VERSION "2"

NS_ :

BS_:

BU_: EyeQ4
VAL_TABLE_ Filter_Type 3 "embedded" 2 "TS on vehicle (truck or bus)" 1 "Irrelevant to the host" ;
VAL_TABLE_ SupplementarySignsTypes 255 "Not in use" 34 "Arrow bidirectional" 33 " Road work au" 32 "area" 31 "Ahead" 30 "Par verglas" 29 "Distance stop" 28 "Reduced ahead" 27 "Minimum" 26 "Advisory" 25 "Exit" 24 "End" 23 "Ramp" 22 "Zone" 21 "Rapel" 20 "Generic supplementary sign" 19 "Night" 18 "Hazardous_Material" 17 "Fog" 16 "Rain_Cloud" 15 "School" 14 "Snow_Rain" 13 "Tractor" 12 "Distance_in" 11 "Weight" 10 "Distance_Arrow" 9 "Truck" 8 "Bend_Arrow_Right" 7 "Bend_Arrow_Left" 6 "ArrowRight" 5 "ArrowLeft" 4 "Time" 3 "Trailer" 2 "Snow" 1 "Rain" ;
VAL_TABLE_ Vision_only_Sign_Type 255 "e_invalid_sign" 254 "No_Sign_Detected" 221 "standardElectronicEndOfNoPassing" 220 "standardElectronicNoPassingStart" 201 "standardRegularEndOfNoPassing" 200 "standardRegularNoPassingStart" 176 "standardRegularEndOfPlaygrArea" 175 "standardRegularPlaygrAreaBegin" 174 "standardRegularEndOfExpressway" 173 "standardRegularExpresswayBegins" 172 "standard regular end of Motorway" 171 "standard regular motorway begins" 129 "standard electronic 145" 128 "standard electronic 135" 127 "standard electronic 125" 126 "standard electronic 115" 125 "standard electronic 105" 124 "standard electronic 95" 123 "standard electronic 85" 122 "standard electronic 75" 121 "standard electronic 65" 120 "standard electronic 55" 119 "standard electronic 45" 118 "standard electronic 35" 117 "standard electronic 25" 116 "standard electronic 15" 115 "standard electronic 5" 114 "standard regular 145" 113 "standard regular 135" 112 "standard regular 125" 111 "standard regular 115" 110 "standard regular 105" 109 "standard regular 95" 108 "standard regular 85" 107 "standard regular 75" 106 "standard regular 65" 105 "standard regular 55" 104 "standard regular 45" 103 "standard regular 35" 102 "standard regular 25" 101 "standard regular 15" 100 "standard regular 5" 65 "standard electronic general" 64 "standard regular general" 50 "end of restriction2" 41 "Standard electronic 140" 40 "Standard electronic 130" 39 "39 Standard electronic 120" 38 "Standard electronic 110" 37 "Standard electronic 100" 36 "Standard electronic 90" 35 "Standard electronic 80" 34 " Standard electronic 70" 33 "Standard electronic 60" 32 "Standard electronic 50" 31 "Standard electronic 40" 30 "Standard electronic 30" 29 "Standard electronic 20" 20 "end of restriction1" 13 "Standard regular 150" 12 "Standard regular 130" 11 "Standard regular 120" 10 "Standard regular 110" 9 "Standard regular 100" 8 "Standard regular 90" 7 "Standard regular 80" 6 "Standard regular 70" 5 "Standard regular 60" 4 "Standard regular 50" 3 "Standard regular 40" 2 "Standard regular 30" 1 "Standard regular 20" 0 "Standard regular 10" ;

BO_ 3221225472 VECTOR__INDEPENDENT_SIG_MSG: 0 Vector__XXX
 SG_ HW_warning_level : 0|2@1+ (1,0) [0|3] "" Vector__XXX
 SG_ TSR_warning_level : 0|3@1+ (1,0) [0|7] "" Vector__XXX
 SG_ R_LDW_availability : 0|1@1+ (1,0) [0|1] "" Vector__XXX
 SG_ PCW : 0|1@1+ (1,0) [0|1] "" Vector__XXX
 SG_ Tamper_Alert : 0|1@1+ (1,0) [0|1] "" Vector__XXX
 SG_ Speed_Format : 0|1@1+ (1,0) [0|1] "" Vector__XXX
 SG_ L_LDW_availability : 0|1@1+ (1,0) [0|1] "" Vector__XXX
 SG_ L_LDW : 0|1@1+ (1,0) [0|1] "" Vector__XXX
 SG_ R_LDW : 0|1@1+ (1,0) [0|1] "" Vector__XXX
 SG_ FCW : 0|1@1+ (1,0) [0|1] "" Vector__XXX
 SG_ Maintenance : 0|1@1+ (1,0) [0|1] "" Vector__XXX
 SG_ Fail_safe : 0|1@1+ (1,0) [0|1] "" Vector__XXX
 SG_ ErrorCode : 0|7@1+ (1,0) [0|127] "" Vector__XXX
 SG_ Headway_valid : 0|1@1+ (1,0) [0|1] "" Vector__XXX
 SG_ Headway_measurements : 0|10@1+ (1,0) [0|1023] "" Vector__XXX
 SG_ TSR_Shape : 0|1@1+ (1,0) [0|1] "" Vector__XXX
 SG_ SLI_Alert : 0|1@1+ (1,0) [0|1] "" Vector__XXX
 SG_ Zero_speed : 0|1@1+ (1,0) [0|1] "" Vector__XXX
 SG_ Hi_Low_beam : 0|1@1+ (1,0) [0|1] "" Vector__XXX
 SG_ FLA_armed : 0|1@1+ (1,0) [0|1] "" Vector__XXX
 SG_ Tiem_indicator : 0|2@1+ (1,0) [0|3] "" Vector__XXX
 SG_ Sound_Type : 0|3@1+ (1,0) [0|7] "" Vector__XXX

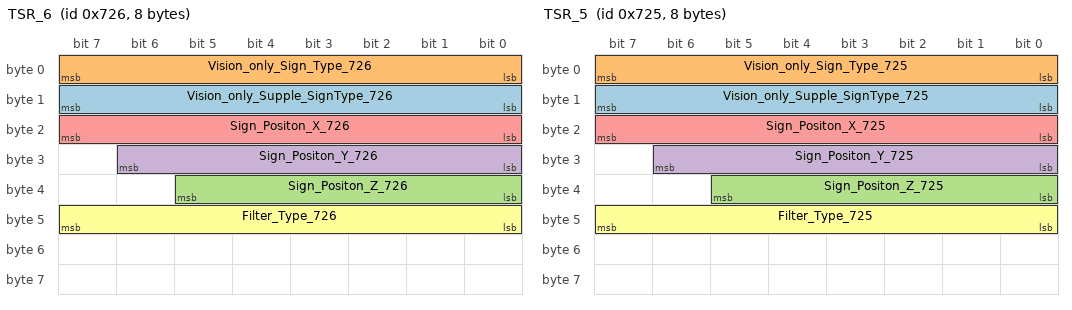
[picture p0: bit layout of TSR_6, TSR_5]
BO_ 1830 TSR_6: 8 EyeQ4
 SG_ Vision_only_Supple_SignType_726 : 8|8@1+ (1,0) [0|255] "" Vector__XXX
 SG_ Vision_only_Sign_Type_726 : 0|8@1+ (1,0) [0|255] "" Vector__XXX
 SG_ Sign_Positon_Z_726 : 32|6@1- (0.5,0) [-16|15.5] "" Vector__XXX
 SG_ Sign_Positon_Y_726 : 24|7@1- (0.5,0) [-32|31.5] "" Vector__XXX
 SG_ Sign_Positon_X_726 : 16|8@1+ (0.5,0) [0|127.5] "" Vector__XXX
 SG_ Filter_Type_726 : 40|8@1+ (1,0) [0|255] "" Vector__XXX

BO_ 1829 TSR_5: 8 EyeQ4
 SG_ Vision_only_Supple_SignType_725 : 8|8@1+ (1,0) [0|255] "" Vector__XXX
 SG_ Vision_only_Sign_Type_725 : 0|8@1+ (1,0) [0|255] "" Vector__XXX
 SG_ Sign_Positon_Z_725 : 32|6@1- (0.5,0) [-16|15.5] "" Vector__XXX
 SG_ Sign_Positon_Y_725 : 24|7@1- (0.5,0) [-32|31.5] "" Vector__XXX
 SG_ Sign_Positon_X_725 : 16|8@1+ (0.5,0) [0|127.5] "" Vector__XXX
 SG_ Filter_Type_725 : 40|8@1+ (1,0) [0|255] "" Vector__XXX

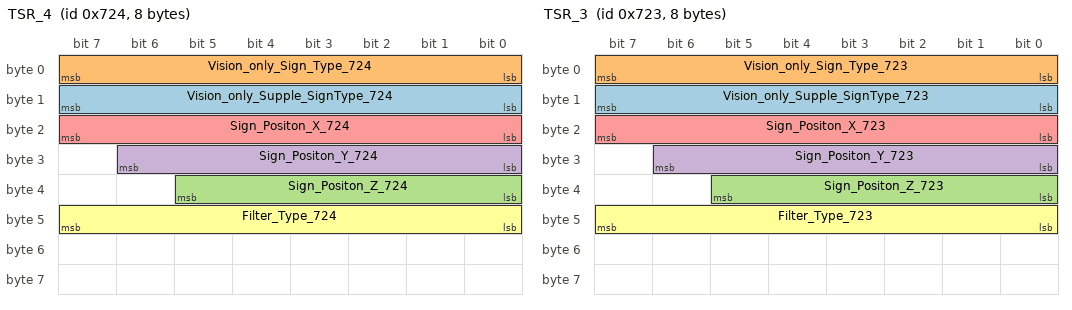
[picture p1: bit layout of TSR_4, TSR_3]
BO_ 1828 TSR_4: 8 EyeQ4
 SG_ Vision_only_Supple_SignType_724 : 8|8@1+ (1,0) [0|255] "" Vector__XXX
 SG_ Vision_only_Sign_Type_724 : 0|8@1+ (1,0) [0|255] "" Vector__XXX
 SG_ Sign_Positon_Z_724 : 32|6@1- (0.5,0) [-16|15.5] "" Vector__XXX
 SG_ Sign_Positon_Y_724 : 24|7@1- (0.5,0) [-32|31.5] "" Vector__XXX
 SG_ Sign_Positon_X_724 : 16|8@1+ (0.5,0) [0|127.5] "" Vector__XXX
 SG_ Filter_Type_724 : 40|8@1+ (1,0) [0|255] "" Vector__XXX

BO_ 1827 TSR_3: 8 EyeQ4
 SG_ Vision_only_Supple_SignType_723 : 8|8@1+ (1,0) [0|255] "" Vector__XXX
 SG_ Vision_only_Sign_Type_723 : 0|8@1+ (1,0) [0|255] "" Vector__XXX
 SG_ Sign_Positon_Z_723 : 32|6@1- (0.5,0) [-16|15.5] "" Vector__XXX
 SG_ Sign_Positon_Y_723 : 24|7@1- (0.5,0) [-32|31.5] "" Vector__XXX
 SG_ Sign_Positon_X_723 : 16|8@1+ (0.5,0) [0|127.5] "" Vector__XXX
 SG_ Filter_Type_723 : 40|8@1+ (1,0) [0|255] "" Vector__XXX

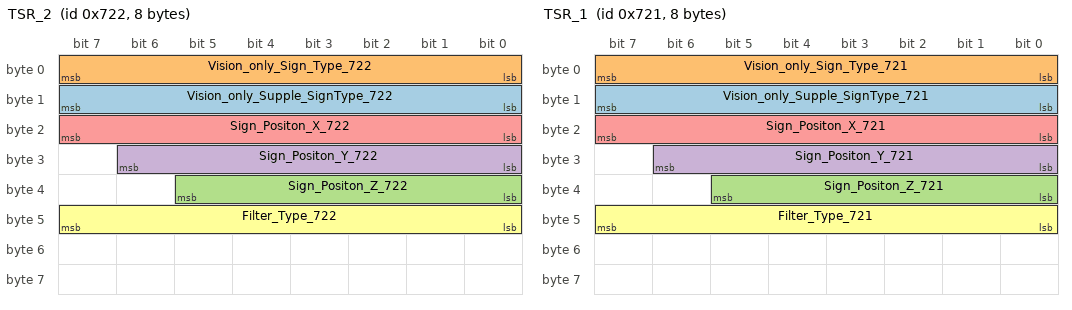
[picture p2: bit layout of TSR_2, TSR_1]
BO_ 1826 TSR_2: 8 EyeQ4
 SG_ Vision_only_Supple_SignType_722 : 8|8@1+ (1,0) [0|255] "" Vector__XXX
 SG_ Vision_only_Sign_Type_722 : 0|8@1+ (1,0) [0|255] "" Vector__XXX
 SG_ Sign_Positon_Z_722 : 32|6@1- (0.5,0) [-16|15.5] "" Vector__XXX
 SG_ Sign_Positon_Y_722 : 24|7@1- (0.5,0) [-32|31.5] "" Vector__XXX
 SG_ Sign_Positon_X_722 : 16|8@1+ (0.5,0) [0|127.5] "" Vector__XXX
 SG_ Filter_Type_722 : 40|8@1+ (1,0) [0|255] "" Vector__XXX

BO_ 1825 TSR_1: 8 EyeQ4
 SG_ Vision_only_Supple_SignType_721 : 8|8@1+ (1,0) [0|255] "" Vector__XXX
 SG_ Vision_only_Sign_Type_721 : 0|8@1+ (1,0) [0|255] "" Vector__XXX
 SG_ Sign_Positon_Z_721 : 32|6@1- (0.5,0) [-16|15.5] "" Vector__XXX
 SG_ Sign_Positon_Y_721 : 24|7@1- (0.5,0) [-32|31.5] "" Vector__XXX
 SG_ Sign_Positon_X_721 : 16|8@1+ (0.5,0) [0|127.5] "" Vector__XXX
 SG_ Filter_Type_721 : 40|8@1+ (1,0) [0|255] "" Vector__XXX

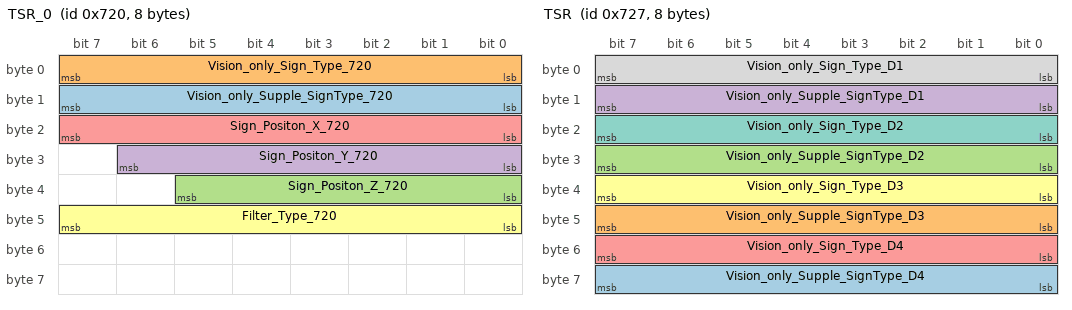
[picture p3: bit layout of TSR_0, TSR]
BO_ 1824 TSR_0: 8 EyeQ4
 SG_ Vision_only_Supple_SignType_720 : 8|8@1+ (1,0) [0|255] "" Vector__XXX
 SG_ Vision_only_Sign_Type_720 : 0|8@1+ (1,0) [0|255] "" Vector__XXX
 SG_ Sign_Positon_Z_720 : 32|6@1- (0.5,0) [-16|15.5] "" Vector__XXX
 SG_ Sign_Positon_Y_720 : 24|7@1- (0.5,0) [-32|31.5] "" Vector__XXX
 SG_ Sign_Positon_X_720 : 16|8@1+ (0.5,0) [0|127.5] "" Vector__XXX
 SG_ Filter_Type_720 : 40|8@1+ (1,0) [0|255] "" Vector__XXX

BO_ 1831 TSR: 8 EyeQ4
 SG_ Vision_only_Supple_SignType_D4 : 56|8@1+ (1,0) [0|255] "" Vector__XXX
 SG_ Vision_only_Supple_SignType_D3 : 40|8@1+ (1,0) [0|255] "" Vector__XXX
 SG_ Vision_only_Supple_SignType_D2 : 24|8@1+ (1,0) [0|255] "" Vector__XXX
 SG_ Vision_only_Supple_SignType_D1 : 8|8@1+ (1,0) [0|255] "" Vector__XXX
 SG_ Vision_only_Sign_Type_D4 : 48|8@1+ (1,0) [0|255] "" Vector__XXX
 SG_ Vision_only_Sign_Type_D3 : 32|8@1+ (1,0) [0|255] "" Vector__XXX
 SG_ Vision_only_Sign_Type_D2 : 16|8@1+ (1,0) [0|255] "" Vector__XXX
 SG_ Vision_only_Sign_Type_D1 : 0|8@1+ (1,0) [0|255] "" Vector__XXX

CM_ BO_ 3221225472 "This is a message for not used signals, created by Vector CANdb++ DBC OLE DB Provider.";
BA_DEF_  "BusType" STRING ;
BA_DEF_DEF_  "BusType" "CAN";
VAL_ 1830 Vision_only_Supple_SignType_726 255 "Not in use" 34 "Arrow bidirectional" 33 " Road work au" 32 "area" 31 "Ahead" 30 "Par verglas" 29 "Distance stop" 28 "Reduced ahead" 27 "Minimum" 26 "Advisory" 25 "Exit" 24 "End" 23 "Ramp" 22 "Zone" 21 "Rapel" 20 "Generic supplementary sign" 19 "Night" 18 "Hazardous_Material" 17 "Fog" 16 "Rain_Cloud" 15 "School" 14 "Snow_Rain" 13 "Tractor" 12 "Distance_in" 11 "Weight" 10 "Distance_Arrow" 9 "Truck" 8 "Bend_Arrow_Right" 7 "Bend_Arrow_Left" 6 "ArrowRight" 5 "ArrowLeft" 4 "Time" 3 "Trailer" 2 "Snow" 1 "Rain" ;
VAL_ 1830 Vision_only_Sign_Type_726 255 "e_invalid_sign" 254 "No_Sign_Detected" 221 "standardElectronicEndOfNoPassing" 220 "standardElectronicNoPassingStart" 201 "standardRegularEndOfNoPassing" 200 "standardRegularNoPassingStart" 176 "standardRegularEndOfPlaygrArea" 175 "standardRegularPlaygrAreaBegin" 174 "standardRegularEndOfExpressway" 173 "standardRegularExpresswayBegins" 172 "standard regular end of Motorway" 171 "standard regular motorway begins" 129 "standard electronic 145" 128 "standard electronic 135" 127 "standard electronic 125" 126 "standard electronic 115" 125 "standard electronic 105" 124 "standard electronic 95" 123 "standard electronic 85" 122 "standard electronic 75" 121 "standard electronic 65" 120 "standard electronic 55" 119 "standard electronic 45" 118 "standard electronic 35" 117 "standard electronic 25" 116 "standard electronic 15" 115 "standard electronic 5" 114 "standard regular 145" 113 "standard regular 135" 112 "standard regular 125" 111 "standard regular 115" 110 "standard regular 105" 109 "standard regular 95" 108 "standard regular 85" 107 "standard regular 75" 106 "standard regular 65" 105 "standard regular 55" 104 "standard regular 45" 103 "standard regular 35" 102 "standard regular 25" 101 "standard regular 15" 100 "standard regular 5" 65 "standard electronic general" 64 "standard regular general" 50 "end of restriction2" 41 "Standard electronic 140" 40 "Standard electronic 130" 39 "39 Standard electronic 120" 38 "Standard electronic 110" 37 "Standard electronic 100" 36 "Standard electronic 90" 35 "Standard electronic 80" 34 " Standard electronic 70" 33 "Standard electronic 60" 32 "Standard electronic 50" 31 "Standard electronic 40" 30 "Standard electronic 30" 29 "Standard electronic 20" 20 "end of restriction1" 13 "Standard regular 150" 12 "Standard regular 130" 11 "Standard regular 120" 10 "Standard regular 110" 9 "Standard regular 100" 8 "Standard regular 90" 7 "Standard regular 80" 6 "Standard regular 70" 5 "Standard regular 60" 4 "Standard regular 50" 3 "Standard regular 40" 2 "Standard regular 30" 1 "Standard regular 20" 0 "Standard regular 10" ;
VAL_ 1830 Filter_Type_726 3 "embedded" 2 "TS on vehicle (truck or bus)" 1 "Irrelevant to the host" ;
VAL_ 1829 Vision_only_Supple_SignType_725 255 "Not in use" 34 "Arrow bidirectional" 33 " Road work au" 32 "area" 31 "Ahead" 30 "Par verglas" 29 "Distance stop" 28 "Reduced ahead" 27 "Minimum" 26 "Advisory" 25 "Exit" 24 "End" 23 "Ramp" 22 "Zone" 21 "Rapel" 20 "Generic supplementary sign" 19 "Night" 18 "Hazardous_Material" 17 "Fog" 16 "Rain_Cloud" 15 "School" 14 "Snow_Rain" 13 "Tractor" 12 "Distance_in" 11 "Weight" 10 "Distance_Arrow" 9 "Truck" 8 "Bend_Arrow_Right" 7 "Bend_Arrow_Left" 6 "ArrowRight" 5 "ArrowLeft" 4 "Time" 3 "Trailer" 2 "Snow" 1 "Rain" ;
VAL_ 1829 Vision_only_Sign_Type_725 255 "e_invalid_sign" 254 "No_Sign_Detected" 221 "standardElectronicEndOfNoPassing" 220 "standardElectronicNoPassingStart" 201 "standardRegularEndOfNoPassing" 200 "standardRegularNoPassingStart" 176 "standardRegularEndOfPlaygrArea" 175 "standardRegularPlaygrAreaBegin" 174 "standardRegularEndOfExpressway" 173 "standardRegularExpresswayBegins" 172 "standard regular end of Motorway" 171 "standard regular motorway begins" 129 "standard electronic 145" 128 "standard electronic 135" 127 "standard electronic 125" 126 "standard electronic 115" 125 "standard electronic 105" 124 "standard electronic 95" 123 "standard electronic 85" 122 "standard electronic 75" 121 "standard electronic 65" 120 "standard electronic 55" 119 "standard electronic 45" 118 "standard electronic 35" 117 "standard electronic 25" 116 "standard electronic 15" 115 "standard electronic 5" 114 "standard regular 145" 113 "standard regular 135" 112 "standard regular 125" 111 "standard regular 115" 110 "standard regular 105" 109 "standard regular 95" 108 "standard regular 85" 107 "standard regular 75" 106 "standard regular 65" 105 "standard regular 55" 104 "standard regular 45" 103 "standard regular 35" 102 "standard regular 25" 101 "standard regular 15" 100 "standard regular 5" 65 "standard electronic general" 64 "standard regular general" 50 "end of restriction2" 41 "Standard electronic 140" 40 "Standard electronic 130" 39 "39 Standard electronic 120" 38 "Standard electronic 110" 37 "Standard electronic 100" 36 "Standard electronic 90" 35 "Standard electronic 80" 34 " Standard electronic 70" 33 "Standard electronic 60" 32 "Standard electronic 50" 31 "Standard electronic 40" 30 "Standard electronic 30" 29 "Standard electronic 20" 20 "end of restriction1" 13 "Standard regular 150" 12 "Standard regular 130" 11 "Standard regular 120" 10 "Standard regular 110" 9 "Standard regular 100" 8 "Standard regular 90" 7 "Standard regular 80" 6 "Standard regular 70" 5 "Standard regular 60" 4 "Standard regular 50" 3 "Standard regular 40" 2 "Standard regular 30" 1 "Standard regular 20" 0 "Standard regular 10" ;
VAL_ 1829 Filter_Type_725 3 "embedded" 2 "TS on vehicle (truck or bus)" 1 "Irrelevant to the host" ;
VAL_ 1828 Vision_only_Supple_SignType_724 255 "Not in use" 34 "Arrow bidirectional" 33 " Road work au" 32 "area" 31 "Ahead" 30 "Par verglas" 29 "Distance stop" 28 "Reduced ahead" 27 "Minimum" 26 "Advisory" 25 "Exit" 24 "End" 23 "Ramp" 22 "Zone" 21 "Rapel" 20 "Generic supplementary sign" 19 "Night" 18 "Hazardous_Material" 17 "Fog" 16 "Rain_Cloud" 15 "School" 14 "Snow_Rain" 13 "Tractor" 12 "Distance_in" 11 "Weight" 10 "Distance_Arrow" 9 "Truck" 8 "Bend_Arrow_Right" 7 "Bend_Arrow_Left" 6 "ArrowRight" 5 "ArrowLeft" 4 "Time" 3 "Trailer" 2 "Snow" 1 "Rain" ;
VAL_ 1828 Vision_only_Sign_Type_724 255 "e_invalid_sign" 254 "No_Sign_Detected" 221 "standardElectronicEndOfNoPassing" 220 "standardElectronicNoPassingStart" 201 "standardRegularEndOfNoPassing" 200 "standardRegularNoPassingStart" 176 "standardRegularEndOfPlaygrArea" 175 "standardRegularPlaygrAreaBegin" 174 "standardRegularEndOfExpressway" 173 "standardRegularExpresswayBegins" 172 "standard regular end of Motorway" 171 "standard regular motorway begins" 129 "standard electronic 145" 128 "standard electronic 135" 127 "standard electronic 125" 126 "standard electronic 115" 125 "standard electronic 105" 124 "standard electronic 95" 123 "standard electronic 85" 122 "standard electronic 75" 121 "standard electronic 65" 120 "standard electronic 55" 119 "standard electronic 45" 118 "standard electronic 35" 117 "standard electronic 25" 116 "standard electronic 15" 115 "standard electronic 5" 114 "standard regular 145" 113 "standard regular 135" 112 "standard regular 125" 111 "standard regular 115" 110 "standard regular 105" 109 "standard regular 95" 108 "standard regular 85" 107 "standard regular 75" 106 "standard regular 65" 105 "standard regular 55" 104 "standard regular 45" 103 "standard regular 35" 102 "standard regular 25" 101 "standard regular 15" 100 "standard regular 5" 65 "standard electronic general" 64 "standard regular general" 50 "end of restriction2" 41 "Standard electronic 140" 40 "Standard electronic 130" 39 "39 Standard electronic 120" 38 "Standard electronic 110" 37 "Standard electronic 100" 36 "Standard electronic 90" 35 "Standard electronic 80" 34 " Standard electronic 70" 33 "Standard electronic 60" 32 "Standard electronic 50" 31 "Standard electronic 40" 30 "Standard electronic 30" 29 "Standard electronic 20" 20 "end of restriction1" 13 "Standard regular 150" 12 "Standard regular 130" 11 "Standard regular 120" 10 "Standard regular 110" 9 "Standard regular 100" 8 "Standard regular 90" 7 "Standard regular 80" 6 "Standard regular 70" 5 "Standard regular 60" 4 "Standard regular 50" 3 "Standard regular 40" 2 "Standard regular 30" 1 "Standard regular 20" 0 "Standard regular 10" ;
VAL_ 1828 Filter_Type_724 3 "embedded" 2 "TS on vehicle (truck or bus)" 1 "Irrelevant to the host" ;
VAL_ 1827 Vision_only_Supple_SignType_723 255 "Not in use" 34 "Arrow bidirectional" 33 " Road work au" 32 "area" 31 "Ahead" 30 "Par verglas" 29 "Distance stop" 28 "Reduced ahead" 27 "Minimum" 26 "Advisory" 25 "Exit" 24 "End" 23 "Ramp" 22 "Zone" 21 "Rapel" 20 "Generic supplementary sign" 19 "Night" 18 "Hazardous_Material" 17 "Fog" 16 "Rain_Cloud" 15 "School" 14 "Snow_Rain" 13 "Tractor" 12 "Distance_in" 11 "Weight" 10 "Distance_Arrow" 9 "Truck" 8 "Bend_Arrow_Right" 7 "Bend_Arrow_Left" 6 "ArrowRight" 5 "ArrowLeft" 4 "Time" 3 "Trailer" 2 "Snow" 1 "Rain" ;
VAL_ 1827 Vision_only_Sign_Type_723 255 "e_invalid_sign" 254 "No_Sign_Detected" 221 "standardElectronicEndOfNoPassing" 220 "standardElectronicNoPassingStart" 201 "standardRegularEndOfNoPassing" 200 "standardRegularNoPassingStart" 176 "standardRegularEndOfPlaygrArea" 175 "standardRegularPlaygrAreaBegin" 174 "standardRegularEndOfExpressway" 173 "standardRegularExpresswayBegins" 172 "standard regular end of Motorway" 171 "standard regular motorway begins" 129 "standard electronic 145" 128 "standard electronic 135" 127 "standard electronic 125" 126 "standard electronic 115" 125 "standard electronic 105" 124 "standard electronic 95" 123 "standard electronic 85" 122 "standard electronic 75" 121 "standard electronic 65" 120 "standard electronic 55" 119 "standard electronic 45" 118 "standard electronic 35" 117 "standard electronic 25" 116 "standard electronic 15" 115 "standard electronic 5" 114 "standard regular 145" 113 "standard regular 135" 112 "standard regular 125" 111 "standard regular 115" 110 "standard regular 105" 109 "standard regular 95" 108 "standard regular 85" 107 "standard regular 75" 106 "standard regular 65" 105 "standard regular 55" 104 "standard regular 45" 103 "standard regular 35" 102 "standard regular 25" 101 "standard regular 15" 100 "standard regular 5" 65 "standard electronic general" 64 "standard regular general" 50 "end of restriction2" 41 "Standard electronic 140" 40 "Standard electronic 130" 39 "39 Standard electronic 120" 38 "Standard electronic 110" 37 "Standard electronic 100" 36 "Standard electronic 90" 35 "Standard electronic 80" 34 " Standard electronic 70" 33 "Standard electronic 60" 32 "Standard electronic 50" 31 "Standard electronic 40" 30 "Standard electronic 30" 29 "Standard electronic 20" 20 "end of restriction1" 13 "Standard regular 150" 12 "Standard regular 130" 11 "Standard regular 120" 10 "Standard regular 110" 9 "Standard regular 100" 8 "Standard regular 90" 7 "Standard regular 80" 6 "Standard regular 70" 5 "Standard regular 60" 4 "Standard regular 50" 3 "Standard regular 40" 2 "Standard regular 30" 1 "Standard regular 20" 0 "Standard regular 10" ;
VAL_ 1827 Filter_Type_723 3 "embedded" 2 "TS on vehicle (truck or bus)" 1 "Irrelevant to the host" ;
VAL_ 1826 Vision_only_Supple_SignType_722 255 "Not in use" 34 "Arrow bidirectional" 33 " Road work au" 32 "area" 31 "Ahead" 30 "Par verglas" 29 "Distance stop" 28 "Reduced ahead" 27 "Minimum" 26 "Advisory" 25 "Exit" 24 "End" 23 "Ramp" 22 "Zone" 21 "Rapel" 20 "Generic supplementary sign" 19 "Night" 18 "Hazardous_Material" 17 "Fog" 16 "Rain_Cloud" 15 "School" 14 "Snow_Rain" 13 "Tractor" 12 "Distance_in" 11 "Weight" 10 "Distance_Arrow" 9 "Truck" 8 "Bend_Arrow_Right" 7 "Bend_Arrow_Left" 6 "ArrowRight" 5 "ArrowLeft" 4 "Time" 3 "Trailer" 2 "Snow" 1 "Rain" ;
VAL_ 1826 Vision_only_Sign_Type_722 255 "e_invalid_sign" 254 "No_Sign_Detected" 221 "standardElectronicEndOfNoPassing" 220 "standardElectronicNoPassingStart" 201 "standardRegularEndOfNoPassing" 200 "standardRegularNoPassingStart" 176 "standardRegularEndOfPlaygrArea" 175 "standardRegularPlaygrAreaBegin" 174 "standardRegularEndOfExpressway" 173 "standardRegularExpresswayBegins" 172 "standard regular end of Motorway" 171 "standard regular motorway begins" 129 "standard electronic 145" 128 "standard electronic 135" 127 "standard electronic 125" 126 "standard electronic 115" 125 "standard electronic 105" 124 "standard electronic 95" 123 "standard electronic 85" 122 "standard electronic 75" 121 "standard electronic 65" 120 "standard electronic 55" 119 "standard electronic 45" 118 "standard electronic 35" 117 "standard electronic 25" 116 "standard electronic 15" 115 "standard electronic 5" 114 "standard regular 145" 113 "standard regular 135" 112 "standard regular 125" 111 "standard regular 115" 110 "standard regular 105" 109 "standard regular 95" 108 "standard regular 85" 107 "standard regular 75" 106 "standard regular 65" 105 "standard regular 55" 104 "standard regular 45" 103 "standard regular 35" 102 "standard regular 25" 101 "standard regular 15" 100 "standard regular 5" 65 "standard electronic general" 64 "standard regular general" 50 "end of restriction2" 41 "Standard electronic 140" 40 "Standard electronic 130" 39 "39 Standard electronic 120" 38 "Standard electronic 110" 37 "Standard electronic 100" 36 "Standard electronic 90" 35 "Standard electronic 80" 34 " Standard electronic 70" 33 "Standard electronic 60" 32 "Standard electronic 50" 31 "Standard electronic 40" 30 "Standard electronic 30" 29 "Standard electronic 20" 20 "end of restriction1" 13 "Standard regular 150" 12 "Standard regular 130" 11 "Standard regular 120" 10 "Standard regular 110" 9 "Standard regular 100" 8 "Standard regular 90" 7 "Standard regular 80" 6 "Standard regular 70" 5 "Standard regular 60" 4 "Standard regular 50" 3 "Standard regular 40" 2 "Standard regular 30" 1 "Standard regular 20" 0 "Standard regular 10" ;
VAL_ 1826 Filter_Type_722 3 "embedded" 2 "TS on vehicle (truck or bus)" 1 "Irrelevant to the host" ;
VAL_ 1825 Vision_only_Supple_SignType_721 255 "Not in use" 34 "Arrow bidirectional" 33 " Road work au" 32 "area" 31 "Ahead" 30 "Par verglas" 29 "Distance stop" 28 "Reduced ahead" 27 "Minimum" 26 "Advisory" 25 "Exit" 24 "End" 23 "Ramp" 22 "Zone" 21 "Rapel" 20 "Generic supplementary sign" 19 "Night" 18 "Hazardous_Material" 17 "Fog" 16 "Rain_Cloud" 15 "School" 14 "Snow_Rain" 13 "Tractor" 12 "Distance_in" 11 "Weight" 10 "Distance_Arrow" 9 "Truck" 8 "Bend_Arrow_Right" 7 "Bend_Arrow_Left" 6 "ArrowRight" 5 "ArrowLeft" 4 "Time" 3 "Trailer" 2 "Snow" 1 "Rain" ;
VAL_ 1825 Vision_only_Sign_Type_721 255 "e_invalid_sign" 254 "No_Sign_Detected" 221 "standardElectronicEndOfNoPassing" 220 "standardElectronicNoPassingStart" 201 "standardRegularEndOfNoPassing" 200 "standardRegularNoPassingStart" 176 "standardRegularEndOfPlaygrArea" 175 "standardRegularPlaygrAreaBegin" 174 "standardRegularEndOfExpressway" 173 "standardRegularExpresswayBegins" 172 "standard regular end of Motorway" 171 "standard regular motorway begins" 129 "standard electronic 145" 128 "standard electronic 135" 127 "standard electronic 125" 126 "standard electronic 115" 125 "standard electronic 105" 124 "standard electronic 95" 123 "standard electronic 85" 122 "standard electronic 75" 121 "standard electronic 65" 120 "standard electronic 55" 119 "standard electronic 45" 118 "standard electronic 35" 117 "standard electronic 25" 116 "standard electronic 15" 115 "standard electronic 5" 114 "standard regular 145" 113 "standard regular 135" 112 "standard regular 125" 111 "standard regular 115" 110 "standard regular 105" 109 "standard regular 95" 108 "standard regular 85" 107 "standard regular 75" 106 "standard regular 65" 105 "standard regular 55" 104 "standard regular 45" 103 "standard regular 35" 102 "standard regular 25" 101 "standard regular 15" 100 "standard regular 5" 65 "standard electronic general" 64 "standard regular general" 50 "end of restriction2" 41 "Standard electronic 140" 40 "Standard electronic 130" 39 "39 Standard electronic 120" 38 "Standard electronic 110" 37 "Standard electronic 100" 36 "Standard electronic 90" 35 "Standard electronic 80" 34 " Standard electronic 70" 33 "Standard electronic 60" 32 "Standard electronic 50" 31 "Standard electronic 40" 30 "Standard electronic 30" 29 "Standard electronic 20" 20 "end of restriction1" 13 "Standard regular 150" 12 "Standard regular 130" 11 "Standard regular 120" 10 "Standard regular 110" 9 "Standard regular 100" 8 "Standard regular 90" 7 "Standard regular 80" 6 "Standard regular 70" 5 "Standard regular 60" 4 "Standard regular 50" 3 "Standard regular 40" 2 "Standard regular 30" 1 "Standard regular 20" 0 "Standard regular 10" ;
VAL_ 1825 Filter_Type_721 3 "embedded" 2 "TS on vehicle (truck or bus)" 1 "Irrelevant to the host" ;
VAL_ 1824 Vision_only_Supple_SignType_720 255 "Not in use" 34 "Arrow bidirectional" 33 " Road work au" 32 "area" 31 "Ahead" 30 "Par verglas" 29 "Distance stop" 28 "Reduced ahead" 27 "Minimum" 26 "Advisory" 25 "Exit" 24 "End" 23 "Ramp" 22 "Zone" 21 "Rapel" 20 "Generic supplementary sign" 19 "Night" 18 "Hazardous_Material" 17 "Fog" 16 "Rain_Cloud" 15 "School" 14 "Snow_Rain" 13 "Tractor" 12 "Distance_in" 11 "Weight" 10 "Distance_Arrow" 9 "Truck" 8 "Bend_Arrow_Right" 7 "Bend_Arrow_Left" 6 "ArrowRight" 5 "ArrowLeft" 4 "Time" 3 "Trailer" 2 "Snow" 1 "Rain" ;
VAL_ 1824 Vision_only_Sign_Type_720 255 "e_invalid_sign" 254 "No_Sign_Detected" 221 "standardElectronicEndOfNoPassing" 220 "standardElectronicNoPassingStart" 201 "standardRegularEndOfNoPassing" 200 "standardRegularNoPassingStart" 176 "standardRegularEndOfPlaygrArea" 175 "standardRegularPlaygrAreaBegin" 174 "standardRegularEndOfExpressway" 173 "standardRegularExpresswayBegins" 172 "standard regular end of Motorway" 171 "standard regular motorway begins" 129 "standard electronic 145" 128 "standard electronic 135" 127 "standard electronic 125" 126 "standard electronic 115" 125 "standard electronic 105" 124 "standard electronic 95" 123 "standard electronic 85" 122 "standard electronic 75" 121 "standard electronic 65" 120 "standard electronic 55" 119 "standard electronic 45" 118 "standard electronic 35" 117 "standard electronic 25" 116 "standard electronic 15" 115 "standard electronic 5" 114 "standard regular 145" 113 "standard regular 135" 112 "standard regular 125" 111 "standard regular 115" 110 "standard regular 105" 109 "standard regular 95" 108 "standard regular 85" 107 "standard regular 75" 106 "standard regular 65" 105 "standard regular 55" 104 "standard regular 45" 103 "standard regular 35" 102 "standard regular 25" 101 "standard regular 15" 100 "standard regular 5" 65 "standard electronic general" 64 "standard regular general" 50 "end of restriction2" 41 "Standard electronic 140" 40 "Standard electronic 130" 39 "39 Standard electronic 120" 38 "Standard electronic 110" 37 "Standard electronic 100" 36 "Standard electronic 90" 35 "Standard electronic 80" 34 " Standard electronic 70" 33 "Standard electronic 60" 32 "Standard electronic 50" 31 "Standard electronic 40" 30 "Standard electronic 30" 29 "Standard electronic 20" 20 "end of restriction1" 13 "Standard regular 150" 12 "Standard regular 130" 11 "Standard regular 120" 10 "Standard regular 110" 9 "Standard regular 100" 8 "Standard regular 90" 7 "Standard regular 80" 6 "Standard regular 70" 5 "Standard regular 60" 4 "Standard regular 50" 3 "Standard regular 40" 2 "Standard regular 30" 1 "Standard regular 20" 0 "Standard regular 10" ;
VAL_ 1824 Filter_Type_720 3 "embedded" 2 "TS on vehicle (truck or bus)" 1 "Irrelevant to the host" ;
VAL_ 1831 Vision_only_Supple_SignType_D4 255 "Not in use" 34 "Arrow bidirectional" 33 " Road work au" 32 "area" 31 "Ahead" 30 "Par verglas" 29 "Distance stop" 28 "Reduced ahead" 27 "Minimum" 26 "Advisory" 25 "Exit" 24 "End" 23 "Ramp" 22 "Zone" 21 "Rapel" 20 "Generic supplementary sign" 19 "Night" 18 "Hazardous_Material" 17 "Fog" 16 "Rain_Cloud" 15 "School" 14 "Snow_Rain" 13 "Tractor" 12 "Distance_in" 11 "Weight" 10 "Distance_Arrow" 9 "Truck" 8 "Bend_Arrow_Right" 7 "Bend_Arrow_Left" 6 "ArrowRight" 5 "ArrowLeft" 4 "Time" 3 "Trailer" 2 "Snow" 1 "Rain" ;
VAL_ 1831 Vision_only_Supple_SignType_D3 255 "Not in use" 34 "Arrow bidirectional" 33 " Road work au" 32 "area" 31 "Ahead" 30 "Par verglas" 29 "Distance stop" 28 "Reduced ahead" 27 "Minimum" 26 "Advisory" 25 "Exit" 24 "End" 23 "Ramp" 22 "Zone" 21 "Rapel" 20 "Generic supplementary sign" 19 "Night" 18 "Hazardous_Material" 17 "Fog" 16 "Rain_Cloud" 15 "School" 14 "Snow_Rain" 13 "Tractor" 12 "Distance_in" 11 "Weight" 10 "Distance_Arrow" 9 "Truck" 8 "Bend_Arrow_Right" 7 "Bend_Arrow_Left" 6 "ArrowRight" 5 "ArrowLeft" 4 "Time" 3 "Trailer" 2 "Snow" 1 "Rain" ;
VAL_ 1831 Vision_only_Supple_SignType_D2 255 "Not in use" 34 "Arrow bidirectional" 33 " Road work au" 32 "area" 31 "Ahead" 30 "Par verglas" 29 "Distance stop" 28 "Reduced ahead" 27 "Minimum" 26 "Advisory" 25 "Exit" 24 "End" 23 "Ramp" 22 "Zone" 21 "Rapel" 20 "Generic supplementary sign" 19 "Night" 18 "Hazardous_Material" 17 "Fog" 16 "Rain_Cloud" 15 "School" 14 "Snow_Rain" 13 "Tractor" 12 "Distance_in" 11 "Weight" 10 "Distance_Arrow" 9 "Truck" 8 "Bend_Arrow_Right" 7 "Bend_Arrow_Left" 6 "ArrowRight" 5 "ArrowLeft" 4 "Time" 3 "Trailer" 2 "Snow" 1 "Rain" ;
VAL_ 1831 Vision_only_Supple_SignType_D1 255 "Not in use" 34 "Arrow bidirectional" 33 " Road work au" 32 "area" 31 "Ahead" 30 "Par verglas" 29 "Distance stop" 28 "Reduced ahead" 27 "Minimum" 26 "Advisory" 25 "Exit" 24 "End" 23 "Ramp" 22 "Zone" 21 "Rapel" 20 "Generic supplementary sign" 19 "Night" 18 "Hazardous_Material" 17 "Fog" 16 "Rain_Cloud" 15 "School" 14 "Snow_Rain" 13 "Tractor" 12 "Distance_in" 11 "Weight" 10 "Distance_Arrow" 9 "Truck" 8 "Bend_Arrow_Right" 7 "Bend_Arrow_Left" 6 "ArrowRight" 5 "ArrowLeft" 4 "Time" 3 "Trailer" 2 "Snow" 1 "Rain" ;
VAL_ 1831 Vision_only_Sign_Type_D4 255 "e_invalid_sign" 254 "No_Sign_Detected" 221 "standardElectronicEndOfNoPassing" 220 "standardElectronicNoPassingStart" 201 "standardRegularEndOfNoPassing" 200 "standardRegularNoPassingStart" 176 "standardRegularEndOfPlaygrArea" 175 "standardRegularPlaygrAreaBegin" 174 "standardRegularEndOfExpressway" 173 "standardRegularExpresswayBegins" 172 "standard regular end of Motorway" 171 "standard regular motorway begins" 129 "standard electronic 145" 128 "standard electronic 135" 127 "standard electronic 125" 126 "standard electronic 115" 125 "standard electronic 105" 124 "standard electronic 95" 123 "standard electronic 85" 122 "standard electronic 75" 121 "standard electronic 65" 120 "standard electronic 55" 119 "standard electronic 45" 118 "standard electronic 35" 117 "standard electronic 25" 116 "standard electronic 15" 115 "standard electronic 5" 114 "standard regular 145" 113 "standard regular 135" 112 "standard regular 125" 111 "standard regular 115" 110 "standard regular 105" 109 "standard regular 95" 108 "standard regular 85" 107 "standard regular 75" 106 "standard regular 65" 105 "standard regular 55" 104 "standard regular 45" 103 "standard regular 35" 102 "standard regular 25" 101 "standard regular 15" 100 "standard regular 5" 65 "standard electronic general" 64 "standard regular general" 50 "end of restriction2" 41 "Standard electronic 140" 40 "Standard electronic 130" 39 "39 Standard electronic 120" 38 "Standard electronic 110" 37 "Standard electronic 100" 36 "Standard electronic 90" 35 "Standard electronic 80" 34 " Standard electronic 70" 33 "Standard electronic 60" 32 "Standard electronic 50" 31 "Standard electronic 40" 30 "Standard electronic 30" 29 "Standard electronic 20" 20 "end of restriction1" 13 "Standard regular 150" 12 "Standard regular 130" 11 "Standard regular 120" 10 "Standard regular 110" 9 "Standard regular 100" 8 "Standard regular 90" 7 "Standard regular 80" 6 "Standard regular 70" 5 "Standard regular 60" 4 "Standard regular 50" 3 "Standard regular 40" 2 "Standard regular 30" 1 "Standard regular 20" 0 "Standard regular 10" ;
VAL_ 1831 Vision_only_Sign_Type_D3 255 "e_invalid_sign" 254 "No_Sign_Detected" 221 "standardElectronicEndOfNoPassing" 220 "standardElectronicNoPassingStart" 201 "standardRegularEndOfNoPassing" 200 "standardRegularNoPassingStart" 176 "standardRegularEndOfPlaygrArea" 175 "standardRegularPlaygrAreaBegin" 174 "standardRegularEndOfExpressway" 173 "standardRegularExpresswayBegins" 172 "standard regular end of Motorway" 171 "standard regular motorway begins" 129 "standard electronic 145" 128 "standard electronic 135" 127 "standard electronic 125" 126 "standard electronic 115" 125 "standard electronic 105" 124 "standard electronic 95" 123 "standard electronic 85" 122 "standard electronic 75" 121 "standard electronic 65" 120 "standard electronic 55" 119 "standard electronic 45" 118 "standard electronic 35" 117 "standard electronic 25" 116 "standard electronic 15" 115 "standard electronic 5" 114 "standard regular 145" 113 "standard regular 135" 112 "standard regular 125" 111 "standard regular 115" 110 "standard regular 105" 109 "standard regular 95" 108 "standard regular 85" 107 "standard regular 75" 106 "standard regular 65" 105 "standard regular 55" 104 "standard regular 45" 103 "standard regular 35" 102 "standard regular 25" 101 "standard regular 15" 100 "standard regular 5" 65 "standard electronic general" 64 "standard regular general" 50 "end of restriction2" 41 "Standard electronic 140" 40 "Standard electronic 130" 39 "39 Standard electronic 120" 38 "Standard electronic 110" 37 "Standard electronic 100" 36 "Standard electronic 90" 35 "Standard electronic 80" 34 " Standard electronic 70" 33 "Standard electronic 60" 32 "Standard electronic 50" 31 "Standard electronic 40" 30 "Standard electronic 30" 29 "Standard electronic 20" 20 "end of restriction1" 13 "Standard regular 150" 12 "Standard regular 130" 11 "Standard regular 120" 10 "Standard regular 110" 9 "Standard regular 100" 8 "Standard regular 90" 7 "Standard regular 80" 6 "Standard regular 70" 5 "Standard regular 60" 4 "Standard regular 50" 3 "Standard regular 40" 2 "Standard regular 30" 1 "Standard regular 20" 0 "Standard regular 10" ;
VAL_ 1831 Vision_only_Sign_Type_D2 255 "e_invalid_sign" 254 "No_Sign_Detected" 221 "standardElectronicEndOfNoPassing" 220 "standardElectronicNoPassingStart" 201 "standardRegularEndOfNoPassing" 200 "standardRegularNoPassingStart" 176 "standardRegularEndOfPlaygrArea" 175 "standardRegularPlaygrAreaBegin" 174 "standardRegularEndOfExpressway" 173 "standardRegularExpresswayBegins" 172 "standard regular end of Motorway" 171 "standard regular motorway begins" 129 "standard electronic 145" 128 "standard electronic 135" 127 "standard electronic 125" 126 "standard electronic 115" 125 "standard electronic 105" 124 "standard electronic 95" 123 "standard electronic 85" 122 "standard electronic 75" 121 "standard electronic 65" 120 "standard electronic 55" 119 "standard electronic 45" 118 "standard electronic 35" 117 "standard electronic 25" 116 "standard electronic 15" 115 "standard electronic 5" 114 "standard regular 145" 113 "standard regular 135" 112 "standard regular 125" 111 "standard regular 115" 110 "standard regular 105" 109 "standard regular 95" 108 "standard regular 85" 107 "standard regular 75" 106 "standard regular 65" 105 "standard regular 55" 104 "standard regular 45" 103 "standard regular 35" 102 "standard regular 25" 101 "standard regular 15" 100 "standard regular 5" 65 "standard electronic general" 64 "standard regular general" 50 "end of restriction2" 41 "Standard electronic 140" 40 "Standard electronic 130" 39 "39 Standard electronic 120" 38 "Standard electronic 110" 37 "Standard electronic 100" 36 "Standard electronic 90" 35 "Standard electronic 80" 34 " Standard electronic 70" 33 "Standard electronic 60" 32 "Standard electronic 50" 31 "Standard electronic 40" 30 "Standard electronic 30" 29 "Standard electronic 20" 20 "end of restriction1" 13 "Standard regular 150" 12 "Standard regular 130" 11 "Standard regular 120" 10 "Standard regular 110" 9 "Standard regular 100" 8 "Standard regular 90" 7 "Standard regular 80" 6 "Standard regular 70" 5 "Standard regular 60" 4 "Standard regular 50" 3 "Standard regular 40" 2 "Standard regular 30" 1 "Standard regular 20" 0 "Standard regular 10" ;
VAL_ 1831 Vision_only_Sign_Type_D1 255 "e_invalid_sign" 254 "No_Sign_Detected" 221 "standardElectronicEndOfNoPassing" 220 "standardElectronicNoPassingStart" 201 "standardRegularEndOfNoPassing" 200 "standardRegularNoPassingStart" 176 "standardRegularEndOfPlaygrArea" 175 "standardRegularPlaygrAreaBegin" 174 "standardRegularEndOfExpressway" 173 "standardRegularExpresswayBegins" 172 "standard regular end of Motorway" 171 "standard regular motorway begins" 129 "standard electronic 145" 128 "standard electronic 135" 127 "standard electronic 125" 126 "standard electronic 115" 125 "standard electronic 105" 124 "standard electronic 95" 123 "standard electronic 85" 122 "standard electronic 75" 121 "standard electronic 65" 120 "standard electronic 55" 119 "standard electronic 45" 118 "standard electronic 35" 117 "standard electronic 25" 116 "standard electronic 15" 115 "standard electronic 5" 114 "standard regular 145" 113 "standard regular 135" 112 "standard regular 125" 111 "standard regular 115" 110 "standard regular 105" 109 "standard regular 95" 108 "standard regular 85" 107 "standard regular 75" 106 "standard regular 65" 105 "standard regular 55" 104 "standard regular 45" 103 "standard regular 35" 102 "standard regular 25" 101 "standard regular 15" 100 "standard regular 5" 65 "standard electronic general" 64 "standard regular general" 50 "end of restriction2" 41 "Standard electronic 140" 40 "Standard electronic 130" 39 "39 Standard electronic 120" 38 "Standard electronic 110" 37 "Standard electronic 100" 36 "Standard electronic 90" 35 "Standard electronic 80" 34 " Standard electronic 70" 33 "Standard electronic 60" 32 "Standard electronic 50" 31 "Standard electronic 40" 30 "Standard electronic 30" 29 "Standard electronic 20" 20 "end of restriction1" 13 "Standard regular 150" 12 "Standard regular 130" 11 "Standard regular 120" 10 "Standard regular 110" 9 "Standard regular 100" 8 "Standard regular 90" 7 "Standard regular 80" 6 "Standard regular 70" 5 "Standard regular 60" 4 "Standard regular 50" 3 "Standard regular 40" 2 "Standard regular 30" 1 "Standard regular 20" 0 "Standard regular 10" ;
